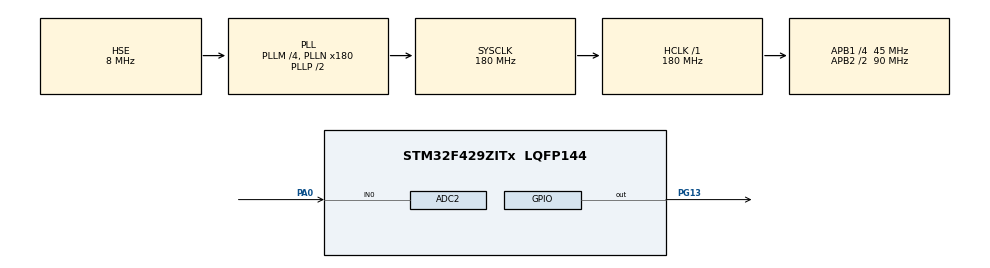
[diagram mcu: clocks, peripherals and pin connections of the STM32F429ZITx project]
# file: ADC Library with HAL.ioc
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ADC1.Channel-0\#ChannelRegularConversion=ADC_CHANNEL_VREFINT
ADC1.ContinuousConvMode=ENABLE
ADC1.NbrOfConversion=1
ADC1.NbrOfConversionFlag=1
ADC1.Rank-0\#ChannelRegularConversion=1
ADC1.SamplingTime-0\#ChannelRegularConversion=ADC_SAMPLETIME_56CYCLES
ADC1.ScanConvMode=DISABLE
ADC1.master=1
ADC2.Channel-0\#ChannelRegularConversion=ADC_CHANNEL_0
ADC2.ContinuousConvMode=ENABLE
ADC2.NbrOfConversionFlag=1
ADC2.Rank-0\#ChannelRegularConversion=1
ADC2.SamplingTime-0\#ChannelRegularConversion=ADC_SAMPLETIME_56CYCLES
Mcu.Family=STM32F4
Mcu.Name=STM32F429ZITx
Mcu.Package=LQFP144
NVIC.PriorityGroup=NVIC_PRIORITYGROUP_4
PA0/WKUP.Signal=ADCx_IN0
PG13.Signal=GPIO_Output
PH0/OSC_IN.Mode=HSE-External-Oscillator
PH0/OSC_IN.Signal=RCC_OSC_IN
PH1/OSC_OUT.Mode=HSE-External-Oscillator
PH1/OSC_OUT.Signal=RCC_OSC_OUT
ProjectManager.HeapSize=0x200
ProjectManager.StackSize=0x400
ProjectManager.TargetToolchain=STM32CubeIDE
RCC.48MHZClocksFreq_Value=90000000
RCC.AHBFreq_Value=180000000
RCC.APB1CLKDivider=RCC_HCLK_DIV4
RCC.APB1Freq_Value=45000000
RCC.APB1TimFreq_Value=90000000
RCC.APB2CLKDivider=RCC_HCLK_DIV2
RCC.APB2Freq_Value=90000000
RCC.APB2TimFreq_Value=180000000
RCC.CortexFreq_Value=180000000
RCC.HCLKFreq_Value=180000000
RCC.HSE_VALUE=8000000
RCC.HSI_VALUE=16000000
RCC.LSE_VALUE=32768
RCC.PLLM=4
RCC.PLLN=180
RCC.PLLSourceVirtual=RCC_PLLSOURCE_HSE
RCC.SYSCLKFreq_VALUE=180000000
RCC.SYSCLKSource=RCC_SYSCLKSOURCE_PLLCLK
RCC.VCOOutputFreq_Value=360000000
SH.ADCx_IN0.0=ADC2_IN0,IN0
VP_ADC1_Vref_Input.Mode=IN-Vrefint
board=custom

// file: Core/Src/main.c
/* USER CODE BEGIN Header */
/**
  ******************************************************************************
  * @file           : main.c
  * @brief          : Main program body
  ******************************************************************************
  * @attention
  *
  * <h2><center>&copy; Copyright (c) 2020 STMicroelectronics.
  * All rights reserved.</center></h2>
  *
  * This software component is licensed by ST under BSD 3-Clause license,
  * the "License"; You may not use this file except in compliance with the
  * License. You may obtain a copy of the License at:
  *                        opensource.org/licenses/BSD-3-Clause
  *
  ******************************************************************************
  */
/* USER CODE END Header */

#include "main.h"

/* USER CODE BEGIN PD */

#define 	VREFIN_CAL		((uint16_t*)((uint32_t)0x1FFF7A2A))

/* USER CODE END PD */

ADC_HandleTypeDef hadc1;
ADC_HandleTypeDef hadc2;

/* USER CODE BEGIN PV */

uint16_t adcValue[2];

float Vadc, Vdda;

int count= 0;

/* USER CODE END PV */

void SystemClock_Config(void);
static void MX_GPIO_Init(void);
static void MX_ADC1_Init(void);
static void MX_ADC2_Init(void);

/* USER CODE BEGIN 0 */

uint16_t Read_ADC(){

	HAL_ADC_Start(&hadc1);
	HAL_ADC_Start(&hadc2);

	if(HAL_ADC_PollForConversion(&hadc1, 1000000) == HAL_OK){

		adcValue[0] = HAL_ADC_GetValue(&hadc1);

		Vdda = (float)3.3 * (*VREFIN_CAL) / adcValue[0];
	}

	if(HAL_ADC_PollForConversion(&hadc2, 1000000) == HAL_OK){

		adcValue[1] = HAL_ADC_GetValue(&hadc2);

		Vadc = Vdda * adcValue[1] / 4095;
	}

	HAL_ADC_Stop(&hadc1);
	HAL_ADC_Stop(&hadc2);
}

/* USER CODE END 0 */

int main(void)
{

  /* MCU Configuration--------------------------------------------------------*/

  /* Reset of all peripherals, Initializes the Flash interface and the Systick. */
  HAL_Init();

  /* Configure the system clock */
  SystemClock_Config();

  /* Initialize all configured peripherals */
  MX_GPIO_Init();
  MX_ADC1_Init();
  MX_ADC2_Init();
  /* USER CODE BEGIN 2 */

 // HAL_ADC_Start(&hadc1);

  /* USER CODE END 2 */

  /* Infinite loop */
  while (1)
  {

    /* USER CODE BEGIN 3 */

	  Read_ADC();

  }
  /* USER CODE END 3 */
}

void SystemClock_Config(void)
{
  RCC_OscInitTypeDef RCC_OscInitStruct = {0};
  RCC_ClkInitTypeDef RCC_ClkInitStruct = {0};

  /** Configure the main internal regulator output voltage
  */
  __HAL_RCC_PWR_CLK_ENABLE();
  __HAL_PWR_VOLTAGESCALING_CONFIG(PWR_REGULATOR_VOLTAGE_SCALE1);
  /** Initializes the CPU, AHB and APB busses clocks
  */
  RCC_OscInitStruct.OscillatorType = RCC_OSCILLATORTYPE_HSE;
  RCC_OscInitStruct.HSEState = RCC_HSE_ON;
  RCC_OscInitStruct.PLL.PLLState = RCC_PLL_ON;
  RCC_OscInitStruct.PLL.PLLSource = RCC_PLLSOURCE_HSE;
  RCC_OscInitStruct.PLL.PLLM = 4;
  RCC_OscInitStruct.PLL.PLLN = 180;
  RCC_OscInitStruct.PLL.PLLP = RCC_PLLP_DIV2;
  RCC_OscInitStruct.PLL.PLLQ = 4;
  if (HAL_RCC_OscConfig(&RCC_OscInitStruct) != HAL_OK)
  {
    Error_Handler();
  }
  /** Activate the Over-Drive mode
  */
  if (HAL_PWREx_EnableOverDrive() != HAL_OK)
  {
    Error_Handler();
  }
  /** Initializes the CPU, AHB and APB busses clocks
  */
  RCC_ClkInitStruct.ClockType = RCC_CLOCKTYPE_HCLK|RCC_CLOCKTYPE_SYSCLK
                              |RCC_CLOCKTYPE_PCLK1|RCC_CLOCKTYPE_PCLK2;
  RCC_ClkInitStruct.SYSCLKSource = RCC_SYSCLKSOURCE_PLLCLK;
  RCC_ClkInitStruct.AHBCLKDivider = RCC_SYSCLK_DIV1;
  RCC_ClkInitStruct.APB1CLKDivider = RCC_HCLK_DIV4;
  RCC_ClkInitStruct.APB2CLKDivider = RCC_HCLK_DIV2;

  if (HAL_RCC_ClockConfig(&RCC_ClkInitStruct, FLASH_LATENCY_5) != HAL_OK)
  {
    Error_Handler();
  }
}

static void MX_ADC1_Init(void)
{

  ADC_ChannelConfTypeDef sConfig = {0};

  /** Configure the global features of the ADC (Clock, Resolution, Data Alignment and number of conversion)
  */
  hadc1.Instance = ADC1;
  hadc1.Init.ClockPrescaler = ADC_CLOCK_SYNC_PCLK_DIV4;
  hadc1.Init.Resolution = ADC_RESOLUTION_12B;
  hadc1.Init.ScanConvMode = DISABLE;
  hadc1.Init.ContinuousConvMode = ENABLE;
  hadc1.Init.DiscontinuousConvMode = DISABLE;
  hadc1.Init.ExternalTrigConvEdge = ADC_EXTERNALTRIGCONVEDGE_NONE;
  hadc1.Init.ExternalTrigConv = ADC_SOFTWARE_START;
  hadc1.Init.DataAlign = ADC_DATAALIGN_RIGHT;
  hadc1.Init.NbrOfConversion = 1;
  hadc1.Init.DMAContinuousRequests = DISABLE;
  hadc1.Init.EOCSelection = ADC_EOC_SINGLE_CONV;
  if (HAL_ADC_Init(&hadc1) != HAL_OK)
  {
    Error_Handler();
  }
  /** Configure for the selected ADC regular channel its corresponding rank in the sequencer and its sample time.
  */
  sConfig.Channel = ADC_CHANNEL_VREFINT;
  sConfig.Rank = 1;
  sConfig.SamplingTime = ADC_SAMPLETIME_56CYCLES;
  if (HAL_ADC_ConfigChannel(&hadc1, &sConfig) != HAL_OK)
  {
    Error_Handler();
  }

}

static void MX_ADC2_Init(void)
{

  ADC_ChannelConfTypeDef sConfig = {0};

  /** Configure the global features of the ADC (Clock, Resolution, Data Alignment and number of conversion)
  */
  hadc2.Instance = ADC2;
  hadc2.Init.ClockPrescaler = ADC_CLOCK_SYNC_PCLK_DIV4;
  hadc2.Init.Resolution = ADC_RESOLUTION_12B;
  hadc2.Init.ScanConvMode = DISABLE;
  hadc2.Init.ContinuousConvMode = ENABLE;
  hadc2.Init.DiscontinuousConvMode = DISABLE;
  hadc2.Init.ExternalTrigConvEdge = ADC_EXTERNALTRIGCONVEDGE_NONE;
  hadc2.Init.ExternalTrigConv = ADC_SOFTWARE_START;
  hadc2.Init.DataAlign = ADC_DATAALIGN_RIGHT;
  hadc2.Init.NbrOfConversion = 1;
  hadc2.Init.DMAContinuousRequests = DISABLE;
  hadc2.Init.EOCSelection = ADC_EOC_SINGLE_CONV;
  if (HAL_ADC_Init(&hadc2) != HAL_OK)
  {
    Error_Handler();
  }
  /** Configure for the selected ADC regular channel its corresponding rank in the sequencer and its sample time.
  */
  sConfig.Channel = ADC_CHANNEL_0;
  sConfig.Rank = 1;
  sConfig.SamplingTime = ADC_SAMPLETIME_56CYCLES;
  if (HAL_ADC_ConfigChannel(&hadc2, &sConfig) != HAL_OK)
  {
    Error_Handler();
  }

}

static void MX_GPIO_Init(void)
{
  GPIO_InitTypeDef GPIO_InitStruct = {0};

  /* GPIO Ports Clock Enable */
  __HAL_RCC_GPIOH_CLK_ENABLE();
  __HAL_RCC_GPIOA_CLK_ENABLE();
  __HAL_RCC_GPIOG_CLK_ENABLE();

  /*Configure GPIO pin Output Level */
  HAL_GPIO_WritePin(GPIOG, GPIO_PIN_13, GPIO_PIN_RESET);

  /*Configure GPIO pin : PG13 */
  GPIO_InitStruct.Pin = GPIO_PIN_13;
  GPIO_InitStruct.Mode = GPIO_MODE_OUTPUT_PP;
  GPIO_InitStruct.Pull = GPIO_NOPULL;
  GPIO_InitStruct.Speed = GPIO_SPEED_FREQ_LOW;
  HAL_GPIO_Init(GPIOG, &GPIO_InitStruct);

}

void Error_Handler(void)
{
}

/************************ (C) COPYRIGHT STMicroelectronics *****END OF FILE****/
